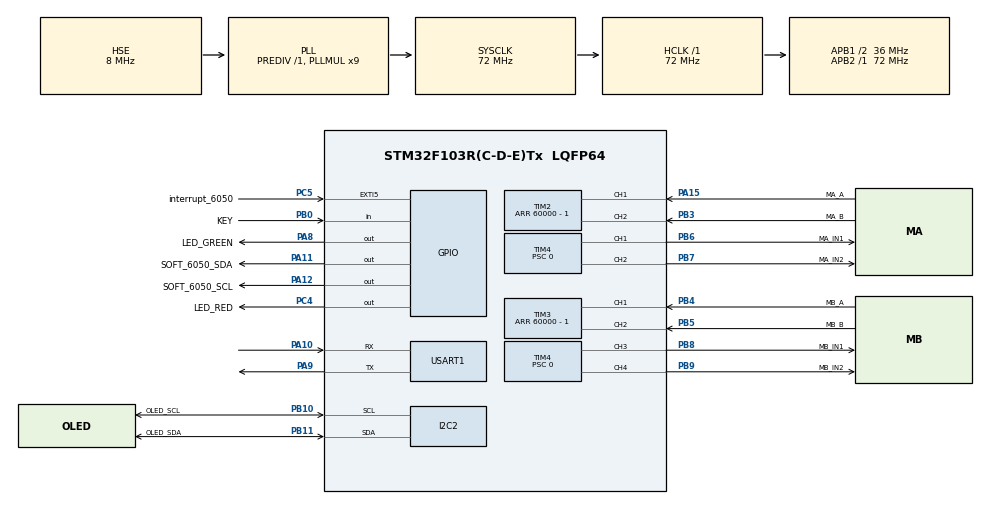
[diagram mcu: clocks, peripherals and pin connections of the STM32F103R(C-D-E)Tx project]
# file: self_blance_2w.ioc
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I2C2.I2C_Mode=I2C_Fast
Mcu.Family=STM32F1
Mcu.Name=STM32F103R(C-D-E)Tx
Mcu.Package=LQFP64
NVIC.EXTI9_5_IRQn=true\:6\:0\:true\:false\:true\:true\:true\:true
NVIC.PriorityGroup=NVIC_PRIORITYGROUP_4
PA10.Mode=Asynchronous
PA10.Signal=USART1_RX
PA11.GPIO_Label=SOFT_6050_SDA
PA11.GPIO_ModeDefaultOutputPP=GPIO_MODE_OUTPUT_OD
PA11.GPIO_PuPd=GPIO_PULLUP
PA11.GPIO_Speed=GPIO_SPEED_FREQ_HIGH
PA11.PinState=GPIO_PIN_SET
PA11.Signal=GPIO_Output
PA12.GPIO_Label=SOFT_6050_SCL
PA12.GPIO_ModeDefaultOutputPP=GPIO_MODE_OUTPUT_OD
PA12.GPIO_PuPd=GPIO_PULLUP
PA12.GPIO_Speed=GPIO_SPEED_FREQ_HIGH
PA12.PinState=GPIO_PIN_SET
PA12.Signal=GPIO_Output
PA13.Mode=Serial_Wire
PA13.Signal=SYS_JTMS-SWDIO
PA14.Mode=Serial_Wire
PA14.Signal=SYS_JTCK-SWCLK
PA15.GPIO_Label=MA_A
PA15.Signal=S_TIM2_CH1_ETR
PA8.GPIO_Label=LED_GREEN
PA8.Signal=GPIO_Output
PA9.Mode=Asynchronous
PA9.Signal=USART1_TX
PB0.GPIO_Label=KEY
PB0.GPIO_PuPd=GPIO_PULLUP
PB0.Signal=GPIO_Input
PB10.GPIO_Label=OLED_SCL
PB10.Mode=I2C
PB10.Signal=I2C2_SCL
PB11.GPIO_Label=OLED_SDA
PB11.Mode=I2C
PB11.Signal=I2C2_SDA
PB3.GPIO_Label=MA_B
PB3.Signal=S_TIM2_CH2
PB4.GPIO_Label=MB_A
PB4.Signal=S_TIM3_CH1
PB5.GPIO_Label=MB_B
PB5.Signal=S_TIM3_CH2
PB6.GPIO_Label=MA_IN1
PB6.Signal=S_TIM4_CH1
PB7.GPIO_Label=MA_IN2
PB7.Signal=S_TIM4_CH2
PB8.GPIO_Label=MB_IN1
PB8.Signal=S_TIM4_CH3
PB9.GPIO_Label=MB_IN2
PB9.Signal=S_TIM4_CH4
PC4.GPIO_Label=LED_RED
PC4.Signal=GPIO_Output
PC5.GPIO_Label=interrupt_6050
PC5.GPIO_ModeDefaultEXTI=GPIO_MODE_IT_FALLING
PC5.GPIO_PuPd=GPIO_PULLUP
PC5.Signal=GPXTI5
PD0-OSC_IN.Mode=HSE-External-Oscillator
PD0-OSC_IN.Signal=RCC_OSC_IN
PD1-OSC_OUT.Mode=HSE-External-Oscillator
PD1-OSC_OUT.Signal=RCC_OSC_OUT
ProjectManager.HeapSize=0x200
ProjectManager.StackSize=0x400
ProjectManager.TargetToolchain=CMake
RCC.AHBFreq_Value=72000000
RCC.APB1CLKDivider=RCC_HCLK_DIV2
RCC.APB1Freq_Value=36000000
RCC.APB1TimFreq_Value=72000000
RCC.APB2Freq_Value=72000000
RCC.APB2TimFreq_Value=72000000
RCC.HCLKFreq_Value=72000000
RCC.PLLMUL=RCC_PLL_MUL9
RCC.PLLSourceVirtual=RCC_PLLSOURCE_HSE
RCC.SYSCLKFreq_VALUE=72000000
RCC.SYSCLKSource=RCC_SYSCLKSOURCE_PLLCLK
RCC.USBFreq_Value=72000000
SH.S_TIM2_CH1_ETR.0=TIM2_CH1,Encoder_Interface
SH.S_TIM2_CH2.0=TIM2_CH2,Encoder_Interface
SH.S_TIM3_CH1.0=TIM3_CH1,Encoder_Interface
SH.S_TIM3_CH2.0=TIM3_CH2,Encoder_Interface
SH.S_TIM4_CH1.0=TIM4_CH1,PWM Generation1 CH1
SH.S_TIM4_CH2.0=TIM4_CH2,PWM Generation2 CH2
SH.S_TIM4_CH3.0=TIM4_CH3,PWM Generation3 CH3
SH.S_TIM4_CH4.0=TIM4_CH4,PWM Generation4 CH4
TIM2.EncoderMode=TIM_ENCODERMODE_TI12
TIM2.IC1Filter=15
TIM2.IC2Filter=15
TIM2.Period=60000 - 1
TIM3.EncoderMode=TIM_ENCODERMODE_TI12
TIM3.IC1Filter=15
TIM3.IC2Filter=15
TIM3.Period=60000 - 1
TIM4.Channel-PWM\ Generation1\ CH1=TIM_CHANNEL_1
TIM4.Channel-PWM\ Generation2\ CH2=TIM_CHANNEL_2
TIM4.Channel-PWM\ Generation3\ CH3=TIM_CHANNEL_3
TIM4.Channel-PWM\ Generation4\ CH4=TIM_CHANNEL_4
TIM4.Period=3600 -1
TIM4.Prescaler=0
TIM5.Prescaler=72 - 1
USART1.VirtualMode=VM_ASYNC
VP_TIM4_VS_ClockSourceINT.Mode=Internal
VP_TIM5_VS_ClockSourceINT.Mode=Internal
board=custom

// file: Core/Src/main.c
/* USER CODE BEGIN Header */
/**
  ******************************************************************************
  * @file           : main.c
  * @brief          : Main program body
  ******************************************************************************
  * @attention
  *
  * Copyright (c) 2025 STMicroelectronics.
  * All rights reserved.
  *
  * This software is licensed under terms that can be found in the LICENSE file
  * in the root directory of this software component.
  * If no LICENSE file comes with this software, it is provided AS-IS.
  *
  ******************************************************************************
  */
/* USER CODE END Header */
#include "main.h"
#include "i2c.h"
#include "tim.h"
#include "usart.h"
#include "gpio.h"

/* USER CODE BEGIN Includes */
#include "common.h"
/* USER CODE END Includes */

void SystemClock_Config(void);

int main(void)
{

  /* MCU Configuration--------------------------------------------------------*/

  /* Reset of all peripherals, Initializes the Flash interface and the Systick. */
  HAL_Init();

  /* Configure the system clock */
  SystemClock_Config();

  /* Initialize all configured peripherals */
  MX_GPIO_Init();
  MX_I2C2_Init();
  MX_USART1_UART_Init();
  MX_TIM2_Init();
  MX_TIM3_Init();
  MX_TIM4_Init();
  MX_TIM5_Init();
  /* USER CODE BEGIN 2 */
  HAL_TIM_Base_Start(&htim5);  // 开启定时器
  OLED_Init();
  MPU6050_Init();
  encoder_init();
  // MPU6050_CheckConnection();
  // test_motor();

  /* USER CODE END 2 */

  /* Infinite loop */
  /* USER CODE BEGIN WHILE */
  while (1)
  {

    mpu_6050_data_ready();

    /* USER CODE END WHILE */

  }
}

void SystemClock_Config(void)
{
  RCC_OscInitTypeDef RCC_OscInitStruct = {0};
  RCC_ClkInitTypeDef RCC_ClkInitStruct = {0};

  /** Initializes the RCC Oscillators according to the specified parameters
  * in the RCC_OscInitTypeDef structure.
  */
  RCC_OscInitStruct.OscillatorType = RCC_OSCILLATORTYPE_HSE;
  RCC_OscInitStruct.HSEState = RCC_HSE_ON;
  RCC_OscInitStruct.HSEPredivValue = RCC_HSE_PREDIV_DIV1;
  RCC_OscInitStruct.HSIState = RCC_HSI_ON;
  RCC_OscInitStruct.PLL.PLLState = RCC_PLL_ON;
  RCC_OscInitStruct.PLL.PLLSource = RCC_PLLSOURCE_HSE;
  RCC_OscInitStruct.PLL.PLLMUL = RCC_PLL_MUL9;
  if (HAL_RCC_OscConfig(&RCC_OscInitStruct) != HAL_OK)
  {
    Error_Handler();
  }

  /** Initializes the CPU, AHB and APB buses clocks
  */
  RCC_ClkInitStruct.ClockType = RCC_CLOCKTYPE_HCLK|RCC_CLOCKTYPE_SYSCLK
                              |RCC_CLOCKTYPE_PCLK1|RCC_CLOCKTYPE_PCLK2;
  RCC_ClkInitStruct.SYSCLKSource = RCC_SYSCLKSOURCE_PLLCLK;
  RCC_ClkInitStruct.AHBCLKDivider = RCC_SYSCLK_DIV1;
  RCC_ClkInitStruct.APB1CLKDivider = RCC_HCLK_DIV2;
  RCC_ClkInitStruct.APB2CLKDivider = RCC_HCLK_DIV1;

  if (HAL_RCC_ClockConfig(&RCC_ClkInitStruct, FLASH_LATENCY_2) != HAL_OK)
  {
    Error_Handler();
  }
}

void Error_Handler(void)
{
  __disable_irq();
  while (1)
  {
  }
}
